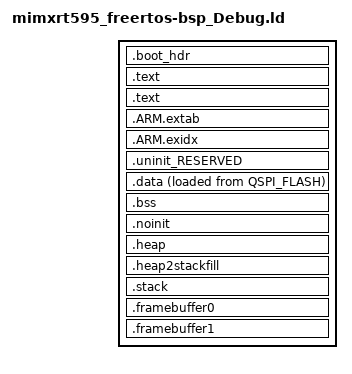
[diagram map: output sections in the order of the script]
/*
 Copyright 2022 MicroEJ Corp. All rights reserved.
 Use of this source code is governed by a BSD-style license that can be found with this software.
*/

INCLUDE "mimxrt595_freertos-bsp_Debug_library.ld"
INCLUDE "mimxrt595_freertos-bsp_Debug_memory.ld"

ENTRY(ResetISR)

SECTIONS
{
     /* Image Vector Table and Boot Data for booting from external flash */
    .boot_hdr : ALIGN(4)
    {
        FILL(0x00)
        __boot_hdr_start__ = ABSOLUTE(.) ;
        . = 0x400 ;
        __flash_conf_hdr_start__ = ABSOLUTE(.) ;
        KEEP(*(.flash_conf))
        __flash_conf_hdr_end__ = ABSOLUTE(.) ;
        . = 0x1000 ;
         __boot_hdr_end__ = ABSOLUTE(.) ;
    } >QSPI_FLASH

    /* MAIN TEXT SECTION */
    .text : ALIGN(4)
    {
        FILL(0xff)
        __vectors_start__ = ABSOLUTE(.) ;
        KEEP(*(.isr_vector))
        /* Global Section Table */
        . = ALIGN(4) ;
        __section_table_start = .;
        __data_section_table = .;
        LONG(LOADADDR(.data));
        LONG(    ADDR(.data));
        LONG(  SIZEOF(.data));
        __data_section_table_end = .;
        __bss_section_table = .;
        LONG(    ADDR(.bss));
        LONG(  SIZEOF(.bss));
        __bss_section_table_end = .;
        __section_table_end = . ;
        /* End of Global Section Table */

        *(.after_vectors*)

    } > QSPI_FLASH

    .text : ALIGN(4)
    {
       *(.text*)
       *(.rodata .rodata.* .constdata .constdata.*)
       . = ALIGN(4);
            /* C++ constructors etc */
            . = ALIGN(4);
            KEEP(*(.init))
            
            . = ALIGN(4);
            __preinit_array_start = .;
            KEEP (*(.preinit_array))
            __preinit_array_end = .;
            
            . = ALIGN(4);
            __init_array_start = .;
            KEEP (*(SORT(.init_array.*)))
            KEEP (*(.init_array))
            __init_array_end = .;
            
            KEEP(*(.fini));
            
            . = ALIGN(4);
            KEEP (*crtbegin.o(.ctors))
            KEEP (*(EXCLUDE_FILE (*crtend.o) .ctors))
            KEEP (*(SORT(.ctors.*)))
            KEEP (*crtend.o(.ctors))
            
            . = ALIGN(4);
            KEEP (*crtbegin.o(.dtors))
            KEEP (*(EXCLUDE_FILE (*crtend.o) .dtors))
            KEEP (*(SORT(.dtors.*)))
            KEEP (*crtend.o(.dtors))
            . = ALIGN(4);
            /* End C++ */
    } > QSPI_FLASH
    /*
     * for exception handling/unwind - some Newlib functions (in common
     * with C++ and STDC++) use this.
     */
    .ARM.extab : ALIGN(4)
    {
        *(.ARM.extab* .gnu.linkonce.armextab.*)
    } > QSPI_FLASH

    .ARM.exidx : ALIGN(4)
    {
        __exidx_start = .;
        *(.ARM.exidx* .gnu.linkonce.armexidx.*)
        __exidx_end = .;
    } > QSPI_FLASH
 
    _etext = .;

    /* MAIN DATA SECTION */
    .uninit_RESERVED (NOLOAD) : ALIGN(4)
    {

        m_data_start = .;
        _start_uninit_RESERVED = .;
        KEEP(*(.bss.$RESERVED*))
       . = ALIGN(4) ;
        _end_uninit_RESERVED = .;
    } > SRAM AT> SRAM

    /* Main DATA section (SRAM) */
    .data : ALIGN(4)
    {
       FILL(0xff)
       _data = . ;
       PROVIDE(__start_data_RAM = .) ;
       PROVIDE(__start_data_SRAM = .) ;
       *(vtable)
       *(.ramfunc*)
       KEEP(*(CodeQuickAccess))
       KEEP(*(DataQuickAccess))
       *(RamFunction)
       *(.data*)
       . = ALIGN(4) ;
       _edata = . ;
       PROVIDE(__end_data_RAM = .) ;
       PROVIDE(__end_data_SRAM = .) ;
    } > SRAM AT>QSPI_FLASH


    /* MAIN BSS SECTION */
    .bss : ALIGN(4)
    {
        _bss = .;
        PROVIDE(__start_bss_RAM = .) ;
        PROVIDE(__start_bss_SRAM = .) ;
        *(.bss*)
        *(COMMON)
        . = ALIGN(8) ;
        *(ICETEA_HEAP)
        . = ALIGN(4) ;
        *(_java_heap)
        *(_java_immortals)
        
        _ebss = .;
        PROVIDE(__end_bss_RAM = .) ;
        PROVIDE(__end_bss_SRAM = .) ;
        PROVIDE(end = .);
    } > SRAM AT> SRAM

    /* DEFAULT NOINIT SECTION */
    .noinit (NOLOAD): ALIGN(4)
    {
        _noinit = .;
        PROVIDE(__start_noinit_RAM = .) ;
        PROVIDE(__start_noinit_SRAM = .) ;
        *(.noinit*)
         . = ALIGN(4) ;
        _end_noinit = .;
       PROVIDE(__end_noinit_RAM = .) ;
       PROVIDE(__end_noinit_SRAM = .) ;
    } > SRAM AT> SRAM

    /*
    	Reserve and place Heap within memory map.
    	Size is maximum identified heap usage + page size (4096).
    	Page size is added as a workaround for an issue in newlib
    	that forces heap section to end on an address align on a
    	page size.
     */
    _HeapSize = 0x20EC;
    .heap :  ALIGN(4)
    {
        _pvHeapStart = .;
        . += _HeapSize;
        . = ALIGN(4);
        _pvHeapLimit = .;
        __HeapLimit = .; /* Add for _sbrk */
    } > SRAM

     _StackSize = 0x1000;
     /* Reserve space in memory for Stack */
    .heap2stackfill  :
    {
        . += _StackSize;
    } > SRAM
    /* Locate actual Stack in memory map */
    .stack :  ALIGN(4)
    {
        _vStackBase = .;
        . = ALIGN(4);
        _vStackTop = . + _StackSize;
    } > SRAM

    m_data_end = .;

    .framebuffer0 (NOLOAD) :
    {
        m_framebuffer0_start = .;
    } > FRAMEBUFFER0 AT> FRAMEBUFFER0
    m_framebuffer0_end = LOADADDR(.framebuffer0) + SIZEOF(.framebuffer0);

    .framebuffer1 (NOLOAD) :
    {
        m_framebuffer1_start = .;
    } > FRAMEBUFFER1 AT> FRAMEBUFFER1
    m_framebuffer1_end = LOADADDR(.framebuffer1) + SIZEOF(.framebuffer1);

    /* Provide basic symbols giving location and size of main text
     * block, including initial values of RW data sections. Note that
     * these will need extending to give a complete picture with
     * complex images (e.g multiple Flash banks).
     */
    _image_start = LOADADDR(.text);
    _image_end = LOADADDR(.data) + SIZEOF(.data);
    _image_size = _image_end - _image_start;

    /* Provide symbols for MIMXRT500 parts for startup code to use
     * to set image to be plain load image or XIP.
     * Config : Plain load image = false
     */
    __imghdr_loadaddress = LOADADDR(.text);
    __imghdr_imagetype = 4;
}
